# haltium_application register map
Vendor: Nordic Semiconductor; Series: nRFHaltium; File version: 1
CPU: CM33 r0p4, little endian, MPU, FPU, 3 interrupt priority bits, 480 interrupts
Registers are 32-bit, read-write, reset 0x0 unless marked. A register's access mark holds for its fields unless they carry their own. Offsets are from the block's base; [hi:lo] are bit positions; lines under a group give offsets from that group; {n}, {i} and the like mark numbered series; 'fields as' and 'values as' point back to an identical list.

## IPCT_NS — IPCT APB registers 0
Base 0x42013000
Same registers: IPCT_S 0x52013000
{0x0+4i} TASKS_SEND[{i}] (i=0..3) wo — Description collection: Send [n] task
  [0] TASKS_SEND — Send [n] task
    1=Trigger task
{0x10+4i} TASKS_ACK[{i}] (i=0..3) wo — Description collection: Acknowledge the RECEIVE[n] event
  [0] TASKS_ACK — Acknowledge the RECEIVE[n] event
    1=Trigger task
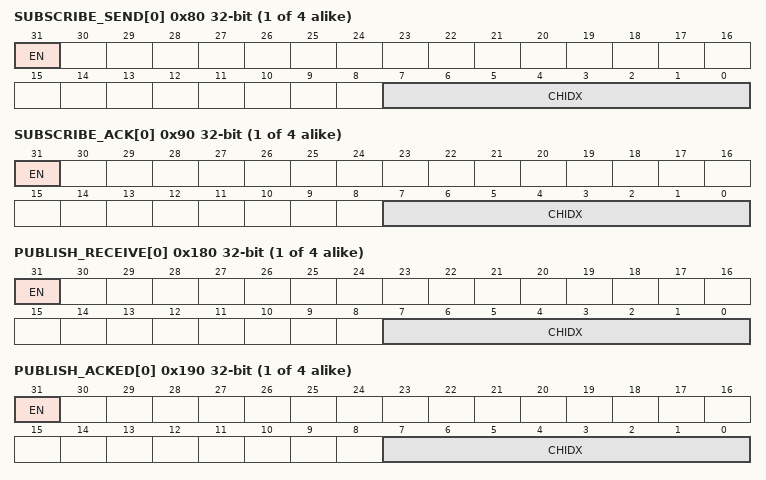
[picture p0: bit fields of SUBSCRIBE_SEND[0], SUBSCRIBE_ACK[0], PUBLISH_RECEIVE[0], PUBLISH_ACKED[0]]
{0x80+4i} SUBSCRIBE_SEND[{i}] (i=0..3) — Description collection: Subscribe configuration for task SEND[n]
  [31] EN
    0=Disabled (Disable subscription); 1=Enabled (Enable subscription)
  [7:0] CHIDX — DPPI channel that task SEND[n] will subscribe to
{0x90+4i} SUBSCRIBE_ACK[{i}] (i=0..3) — Description collection: Subscribe configuration for task ACK[n]
  [31] EN
    values as SUBSCRIBE_SEND[0].EN
  [7:0] CHIDX — DPPI channel that task ACK[n] will subscribe to
{0x100+4i} EVENTS_RECEIVE[{i}] (i=0..3) — Description collection: Receive [n] event
  [0] EVENTS_RECEIVE — Receive [n] event
    0=NotGenerated (Event not generated); 1=Generated (Event generated)
{0x110+4i} EVENTS_ACKED[{i}] (i=0..3) — Description collection: Acknowledged event for the SEND[n] task
  [0] EVENTS_ACKED — Acknowledged event for the SEND[n] task
    values as EVENTS_RECEIVE[0].EVENTS_RECEIVE
{0x180+4i} PUBLISH_RECEIVE[{i}] (i=0..3) — Description collection: Publish configuration for event RECEIVE[n]
  [31] EN
    0=Disabled (Disable publishing); 1=Enabled (Enable publishing)
  [7:0] CHIDX — DPPI channel that event RECEIVE[n] will publish to
{0x190+4i} PUBLISH_ACKED[{i}] (i=0..3) — Description collection: Publish configuration for event ACKED[n]
  [31] EN
    values as PUBLISH_RECEIVE[0].EN
  [7:0] CHIDX — DPPI channel that event ACKED[n] will publish to
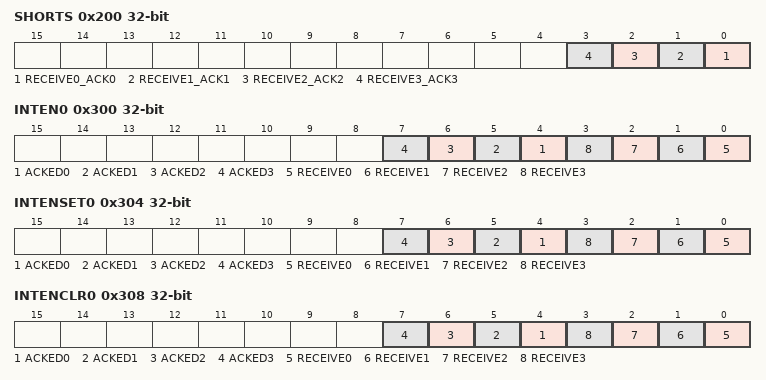
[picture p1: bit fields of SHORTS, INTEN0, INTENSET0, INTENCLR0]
0x200 SHORTS — Shortcuts between local events and tasks
  [all] fields
    0=Disabled (Disable shortcut); 1=Enabled (Enable shortcut)
  [n] RECEIVE{n}_ACK{n} (n=0..3) — Shortcut between event RECEIVE[{n}] and task ACK[{n}]
0x300 INTEN0 — Enable or disable interrupt
  [all] fields
    0=Disabled; 1=Enabled
  [n+4] ACKED{n} (n=0..3) — Enable or disable interrupt for event ACKED[{n}]
  [n] RECEIVE{n} (n=0..3) — Enable or disable interrupt for event RECEIVE[{n}]
0x304 INTENSET0 — Enable interrupt
  [all] fields
    on read: 0=Disabled (Read: Disabled); 1=Enabled (Read: Enabled) | on write: 1=Set (Enable)
  [n+4] ACKED{n} (n=0..3) — Write '1' to enable interrupt for event ACKED[{n}]
  [n] RECEIVE{n} (n=0..3) — Write '1' to enable interrupt for event RECEIVE[{n}]
0x308 INTENCLR0 — Disable interrupt
  [all] fields
    on read: 0=Disabled (Read: Disabled); 1=Enabled (Read: Enabled) | on write: 1=Clear (Disable)
  [n+4] ACKED{n} (n=0..3) — Write '1' to disable interrupt for event ACKED[{n}]
  [n] RECEIVE{n} (n=0..3) — Write '1' to disable interrupt for event RECEIVE[{n}]
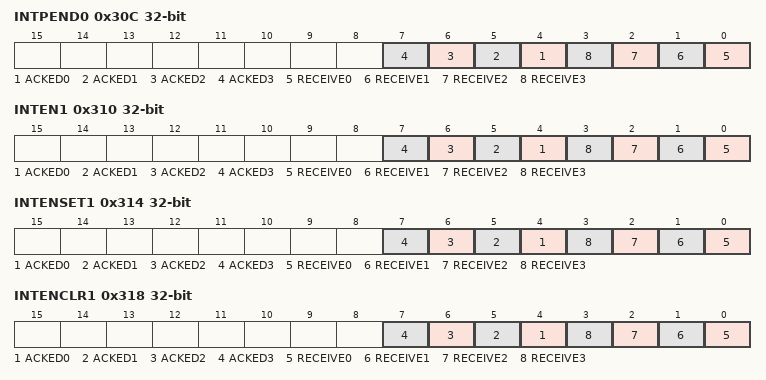
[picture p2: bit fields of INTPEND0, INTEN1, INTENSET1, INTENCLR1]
0x30C INTPEND0 ro — Pending interrupts
  [all] fields
    on read: 0=NotPending (Read: Not pending); 1=Pending (Read: Pending)
  [n+4] ACKED{n} (n=0..3) — Read pending status of interrupt for event ACKED[{n}]
  [n] RECEIVE{n} (n=0..3) — Read pending status of interrupt for event RECEIVE[{n}]
0x310 INTEN1 — Enable or disable interrupt
  fields as INTEN0
0x314 INTENSET1 — Enable interrupt
  fields as INTENSET0
0x318 INTENCLR1 — Disable interrupt
  fields as INTENCLR0
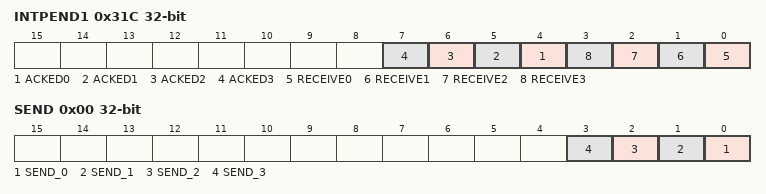
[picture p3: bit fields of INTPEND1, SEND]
0x31C INTPEND1 ro — Pending interrupts
  fields as INTPEND0
0x400 OVERFLOW group — Unspecified
  0x00 SEND — The task overflow status for SEND tasks Write 0 to clear
    [all] fields
      1=Overflow (Task overflow is happened); 0=NoOverflow (Task overflow is not happened)
    [n] SEND_{n} (n=0..3) — The status for SEND [{n}] task overflow
